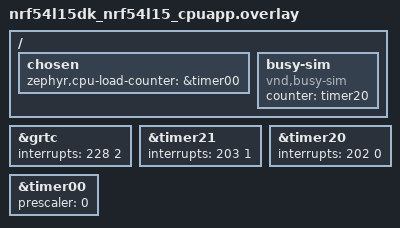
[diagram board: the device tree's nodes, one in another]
/* SPDX-License-Identifier: Apache-2.0 */

&grtc {
	interrupts = <228 2>;
};

test_timer: &timer21 {
	interrupts = <203 1>;
	status = "okay";
};

&timer20 {
	interrupts = <202 0>;
	status = "okay";
};

&timer00 {
	prescaler = <0>;
	status = "okay";
};

/ {
	chosen {
		zephyr,cpu-load-counter = &timer00;
	};

	busy-sim {
		compatible = "vnd,busy-sim";
		counter = <&timer20>;
		status = "okay";
	};
};
